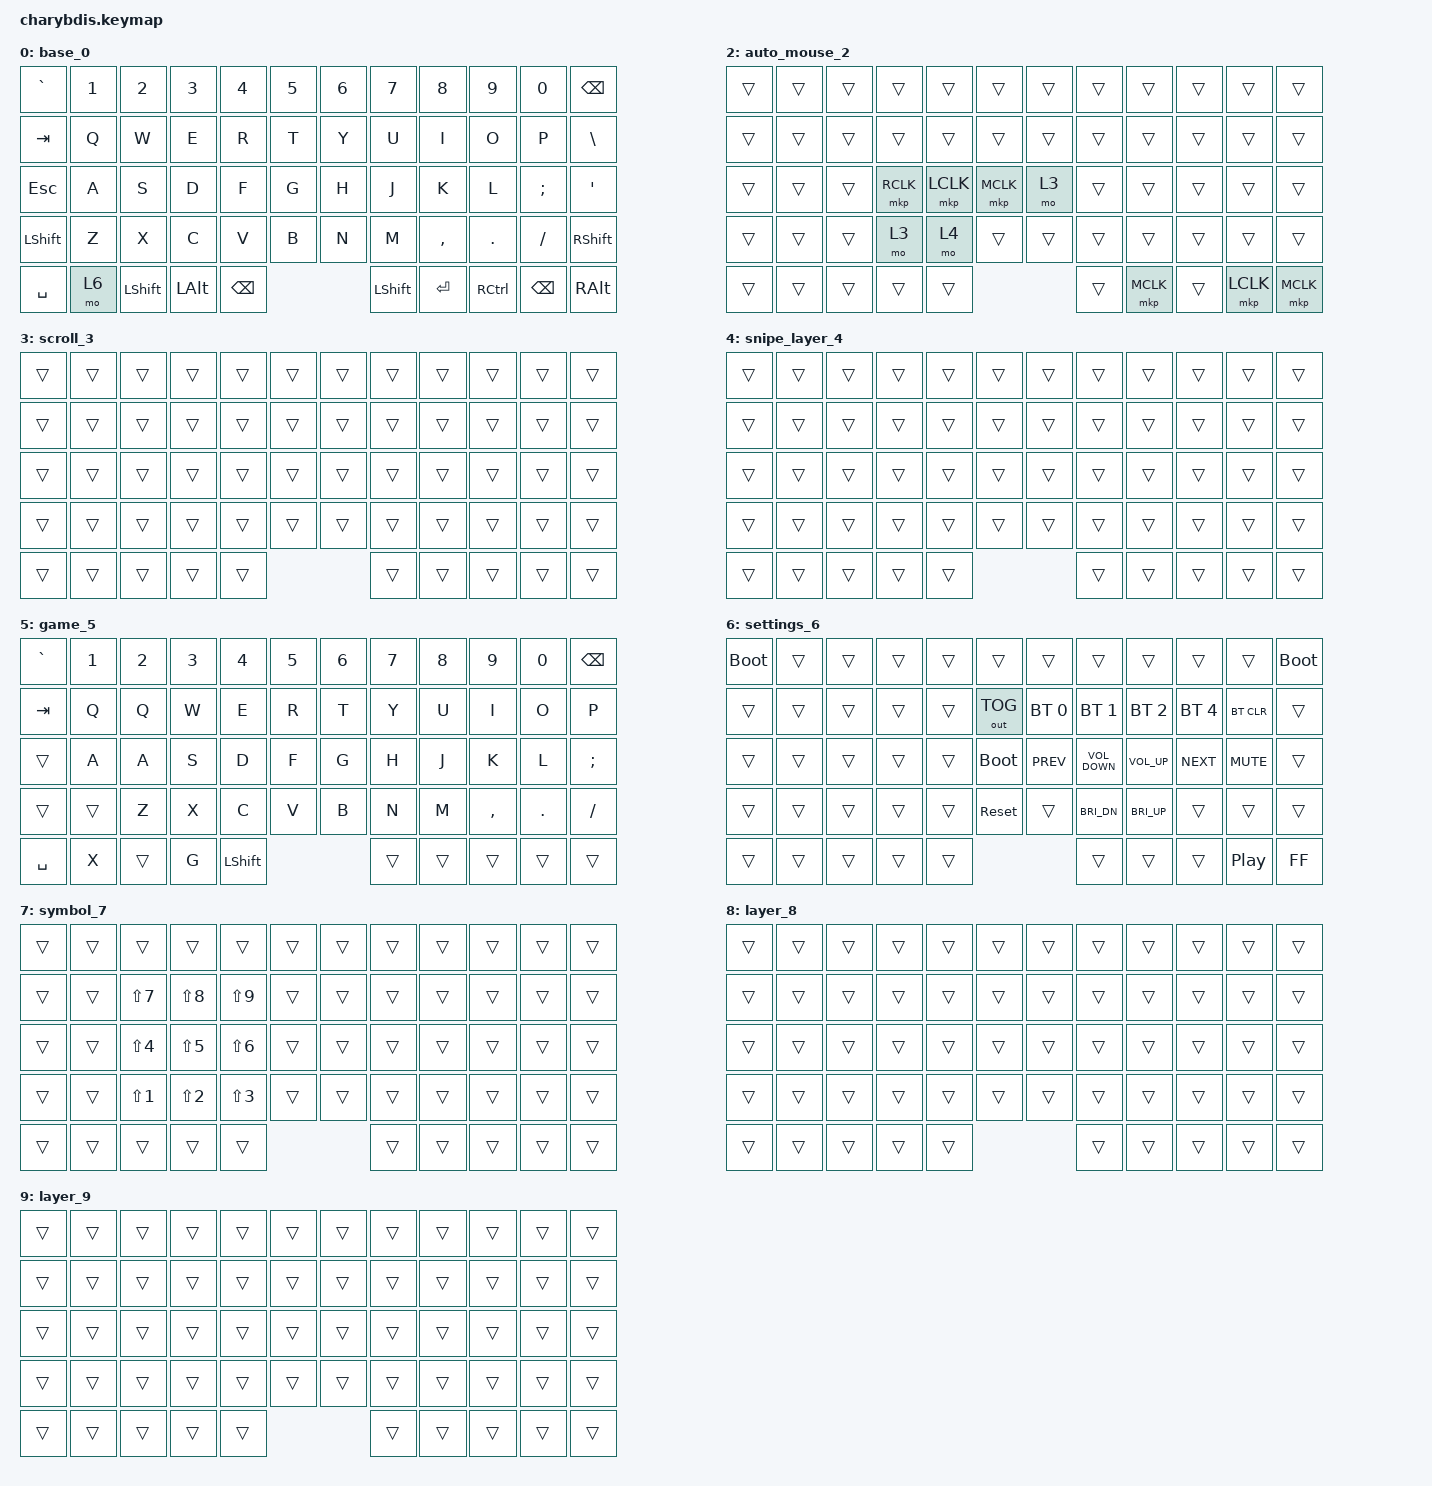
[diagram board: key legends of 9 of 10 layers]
#include <behaviors/mouse_keys.dtsi>
#include <dt-bindings/zmk/mouse.h>
#include <behaviors.dtsi>
#include <dt-bindings/zmk/bt.h>
#include <dt-bindings/zmk/keys.h>
#include <dt-bindings/zmk/outputs.h>
#include <dt-bindings/zmk/pointing.h>

/ {
    behaviors {
        /* hml: homewrow_mods_left { */
        /*     compatible = "zmk,behavior-hold-tap"; */
        /*     label = "homewrow_mods_left"; */
        /*     bindings = <&kp>, <&kp>; */
        /**/
        /*     #binding-cells = <2>; */
        /*     hold-trigger-key-positions = <6 7 8 9 10 11 18 19 20 21 22 23 30 31 32 33 34 35 42 43 44 45 46 47 53 54 55 56 57>; */
        /*     tapping-term-ms = <300>; */
        /*     flavor = "balanced"; */
        /*     quick-tap-ms = <175>; */
        /*     require-prior-idle-ms = <250>; */
        /*     hold-trigger-on-release; */
        /* }; */
        /**/
        /* hmr: hmr { */
        /*     compatible = "zmk,behavior-hold-tap"; */
        /*     label = "HMR"; */
        /*     bindings = <&kp>, <&kp>; */
        /**/
        /*     #binding-cells = <2>; */
        /*     tapping-term-ms = <300>; */
        /*     hold-trigger-key-positions = <0 1 12 13 14 15 16 17 24 25 26 27 28 29 36 37 38 39 40 41 48 49 50 51 52 2 3 4 5>; */
        /*     flavor = "balanced"; */
        /*     quick-tap-ms = <175>; */
        /*     require-prior-idle-ms = <250>; */
        /*     hold-trigger-on-release; */
        /* }; */
        /**/
        /* tap_preferred: tap_preferred { */
        /*     compatible = "zmk,behavior-hold-tap"; */
        /*     label = "TAP_PREFERRED"; */
        /*     bindings = <&mo>, <&kp>; */
        /**/
        /*     #binding-cells = <2>; */
        /*     tapping-term-ms = <40>; */
        /*     flavor = "tap-preferred"; */
        /* }; */
    };

    /* combos { compatible = "zmk,combos"; }; */

    keymap {
        compatible = "zmk,keymap";

        base_0 {
            bindings = <
&kp GRAVE  &kp N1  &kp N2     &kp N3    &kp N4    &kp N5      &kp N6  &kp N7     &kp N8     &kp N9     &kp N0    &kp BSPC
&kp TAB    &kp Q   &kp W      &kp E     &kp R     &kp T       &kp Y   &kp U      &kp I      &kp O      &kp P     &kp BSLH
&kp ESC    &kp A   &kp S      &kp D     &kp F     &kp G       &kp H   &kp J      &kp K      &kp L      &kp SEMI  &kp APOS
&kp LSHFT  &kp Z   &kp X      &kp C     &kp V     &kp B       &kp N   &kp M      &kp COMMA  &kp DOT    &kp FSLH  &kp RSHFT
&kp SPACE  &mo 6   &kp LSHFT  &kp LALT  &kp BSPC                      &kp LSHFT  &kp ENTER  &kp RCTRL  &kp BSPC  &kp RALT
            >;
        };

        number_1 {
            bindings = <
&trans  &trans   &trans  &trans  &trans  &trans         &trans    &trans    &trans        &trans     &trans  &trans
&trans  &trans   &kp N7  &kp N8  &kp N9  &kp PLUS       &trans    &trans    &kp UP        &trans     &trans  &trans
&trans  &trans   &kp N4  &kp N5  &kp N6  &kp MINUS      &kp LEFT  &kp DOWN  &kp UP_ARROW  &kp RIGHT  &trans  &trans
&trans  &kp DOT  &kp N1  &kp N2  &kp N3  &kp N0         &trans    &trans    &trans        &trans     &trans  &trans
&trans  &trans   &trans  &kp N0  &trans                           &trans    &trans        &trans
            >;
        };

        auto_mouse_2 {
            bindings = <
&trans  &trans  &trans  &trans     &trans     &trans         &trans  &trans  &trans     &trans  &trans     &trans
&trans  &trans  &trans  &trans     &trans     &trans         &trans  &trans  &trans     &trans  &trans     &trans
&trans  &trans  &trans  &mkp RCLK  &mkp LCLK  &mkp MCLK      &mo 3   &trans  &trans     &trans  &trans     &trans
&trans  &trans  &trans  &mo 3      &mo 4      &trans         &trans  &trans  &trans     &trans  &trans     &trans
&trans  &trans  &trans  &trans     &trans                            &trans  &mkp MCLK  &trans  &mkp LCLK  &mkp MCLK
            >;
        };

        scroll_3 {
            bindings = <
&trans  &trans  &trans  &trans  &trans  &trans      &trans  &trans  &trans  &trans  &trans  &trans
&trans  &trans  &trans  &trans  &trans  &trans      &trans  &trans  &trans  &trans  &trans  &trans
&trans  &trans  &trans  &trans  &trans  &trans      &trans  &trans  &trans  &trans  &trans  &trans
&trans  &trans  &trans  &trans  &trans  &trans      &trans  &trans  &trans  &trans  &trans  &trans
&trans  &trans  &trans  &trans  &trans                      &trans  &trans  &trans  &trans  &trans
            >;
        };

        snipe_layer_4 {
            bindings = <
&trans  &trans  &trans  &trans  &trans  &trans      &trans  &trans  &trans  &trans  &trans  &trans
&trans  &trans  &trans  &trans  &trans  &trans      &trans  &trans  &trans  &trans  &trans  &trans
&trans  &trans  &trans  &trans  &trans  &trans      &trans  &trans  &trans  &trans  &trans  &trans
&trans  &trans  &trans  &trans  &trans  &trans      &trans  &trans  &trans  &trans  &trans  &trans
&trans  &trans  &trans  &trans  &trans                      &trans  &trans  &trans  &trans  &trans
            >;
        };

        game_5 {
            bindings = <
&kp GRAVE  &kp N1  &kp N2  &kp N3  &kp N4     &kp N5      &kp N6  &kp N7  &kp N8  &kp N9     &kp N0   &kp BSPC
&kp TAB    &kp Q   &kp Q   &kp W   &kp E      &kp R       &kp T   &kp Y   &kp U   &kp I      &kp O    &kp P
&trans     &kp A   &kp A   &kp S   &kp D      &kp F       &kp G   &kp H   &kp J   &kp K      &kp L    &kp SEMI
&trans     &trans  &kp Z   &kp X   &kp C      &kp V       &kp B   &kp N   &kp M   &kp COMMA  &kp DOT  &kp FSLH
&kp SPACE  &kp X   &trans  &kp G   &kp LSHFT                      &trans  &trans  &trans     &trans   &trans
            >;
        };

        settings_6 {
            bindings = <
&bootloader  &trans  &trans  &trans  &trans  &trans            &trans        &trans             &trans           &trans        &trans      &bootloader
&trans       &trans  &trans  &trans  &trans  &out OUT_TOG      &bt BT_SEL 0  &bt BT_SEL 1       &bt BT_SEL 2     &bt BT_SEL 4  &bt BT_CLR  &trans
&trans       &trans  &trans  &trans  &trans  &bootloader       &kp C_PREV    &kp C_VOLUME_DOWN  &kp C_VOLUME_UP  &kp C_NEXT    &kp C_MUTE  &trans
&trans       &trans  &trans  &trans  &trans  &sys_reset        &trans        &kp C_BRI_DN       &kp C_BRI_UP     &trans        &trans      &trans
&trans       &trans  &trans  &trans  &trans                                  &trans             &trans           &trans        &kp C_PP    &kp C_FF
            >;
        };

        symbol_7 {
            bindings = <
&trans  &trans  &trans      &trans      &trans      &trans      &trans  &trans  &trans  &trans  &trans  &trans
&trans  &trans  &kp LS(N7)  &kp LS(N8)  &kp LS(N9)  &trans      &trans  &trans  &trans  &trans  &trans  &trans
&trans  &trans  &kp LS(N4)  &kp LS(N5)  &kp LS(N6)  &trans      &trans  &trans  &trans  &trans  &trans  &trans
&trans  &trans  &kp LS(N1)  &kp LS(N2)  &kp LS(N3)  &trans      &trans  &trans  &trans  &trans  &trans  &trans
&trans  &trans  &trans      &trans      &trans                          &trans  &trans  &trans  &trans  &trans
            >;
        };

        layer_8 {
            bindings = <
&trans  &trans  &trans  &trans  &trans  &trans      &trans  &trans  &trans  &trans  &trans  &trans
&trans  &trans  &trans  &trans  &trans  &trans      &trans  &trans  &trans  &trans  &trans  &trans
&trans  &trans  &trans  &trans  &trans  &trans      &trans  &trans  &trans  &trans  &trans  &trans
&trans  &trans  &trans  &trans  &trans  &trans      &trans  &trans  &trans  &trans  &trans  &trans
&trans  &trans  &trans  &trans  &trans                      &trans  &trans  &trans  &trans  &trans
            >;
        };

        layer_9 {
            bindings = <
&trans  &trans  &trans  &trans  &trans  &trans      &trans  &trans  &trans  &trans  &trans  &trans
&trans  &trans  &trans  &trans  &trans  &trans      &trans  &trans  &trans  &trans  &trans  &trans
&trans  &trans  &trans  &trans  &trans  &trans      &trans  &trans  &trans  &trans  &trans  &trans
&trans  &trans  &trans  &trans  &trans  &trans      &trans  &trans  &trans  &trans  &trans  &trans
&trans  &trans  &trans  &trans  &trans                      &trans  &trans  &trans  &trans  &trans
            >;
        };
    };
};
